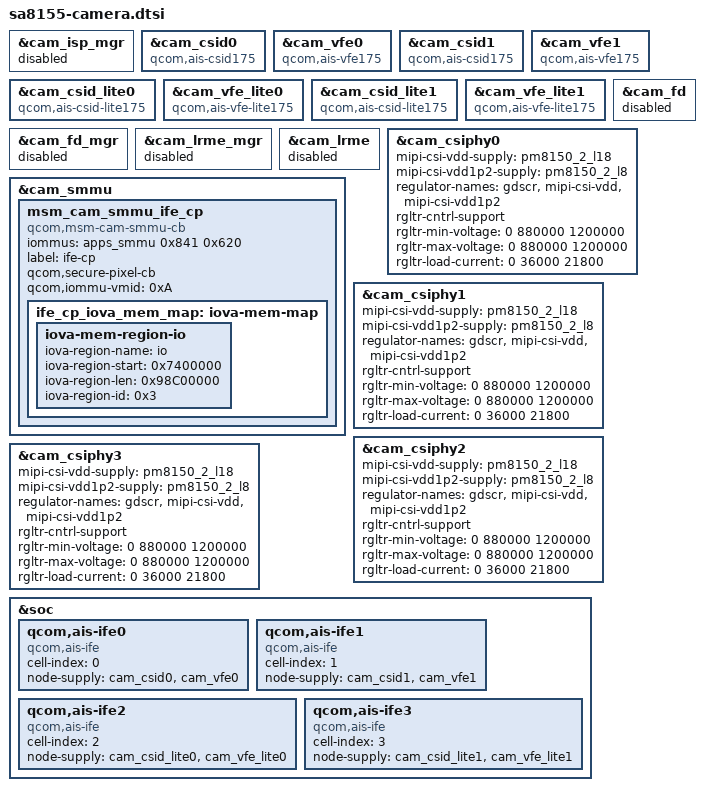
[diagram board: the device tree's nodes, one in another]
#include "sm8150-camera.dtsi"
#include "sa8155-camera-sensor.dtsi"

&cam_isp_mgr {
	status = "disabled";
};

&cam_csid0 {
	compatible = "qcom,ais-csid175";
};

&cam_vfe0 {
	compatible = "qcom,ais-vfe175";
};

&cam_csid1 {
	compatible = "qcom,ais-csid175";
};

&cam_vfe1 {
	compatible = "qcom,ais-vfe175";
};

&cam_csid_lite0 {
	compatible = "qcom,ais-csid-lite175";
};

&cam_vfe_lite0 {
	compatible = "qcom,ais-vfe-lite175";
};

&cam_csid_lite1 {
	compatible = "qcom,ais-csid-lite175";
};

&cam_vfe_lite1 {
	compatible = "qcom,ais-vfe-lite175";
};


&cam_fd_mgr {
	status = "disabled";
};
&cam_fd {
	status = "disabled";
};

&cam_lrme_mgr {
	status = "disabled";
};
&cam_lrme {
	status = "disabled";
};

&cam_smmu {
	msm_cam_smmu_ife_cp {
		compatible = "qcom,msm-cam-smmu-cb";
		iommus = <&apps_smmu 0x841 0x620>;
		label = "ife-cp";
		qcom,secure-pixel-cb;
		qcom,iommu-vmid = <0xA>; /* VMID_CP_PIXEL */
		ife_cp_iova_mem_map: iova-mem-map {
			/* IO region is approximately 2.5 GB */
			iova-mem-region-io {
				iova-region-name = "io";
				iova-region-start = <0x7400000>;
				iova-region-len = <0x98C00000>;
				iova-region-id = <0x3>;
				status = "ok";
			};
		};
	};
};

&cam_csiphy0 {
	mipi-csi-vdd-supply = <&pm8150_2_l18>;
	mipi-csi-vdd1p2-supply = <&pm8150_2_l8>;
	regulator-names = "gdscr", "mipi-csi-vdd", "mipi-csi-vdd1p2";
	rgltr-cntrl-support;
	rgltr-min-voltage = <0 880000 1200000>;
	rgltr-max-voltage = <0 880000 1200000>;
	rgltr-load-current = <0 36000 21800>;
};

&cam_csiphy1 {
	mipi-csi-vdd-supply = <&pm8150_2_l18>;
	mipi-csi-vdd1p2-supply = <&pm8150_2_l8>;
	regulator-names = "gdscr", "mipi-csi-vdd", "mipi-csi-vdd1p2";
	rgltr-cntrl-support;
	rgltr-min-voltage = <0 880000 1200000>;
	rgltr-max-voltage = <0 880000 1200000>;
	rgltr-load-current = <0 36000 21800>;
};

&cam_csiphy2 {
	mipi-csi-vdd-supply = <&pm8150_2_l18>;
	mipi-csi-vdd1p2-supply = <&pm8150_2_l8>;
	regulator-names = "gdscr", "mipi-csi-vdd", "mipi-csi-vdd1p2";
	rgltr-cntrl-support;
	rgltr-min-voltage = <0 880000 1200000>;
	rgltr-max-voltage = <0 880000 1200000>;
	rgltr-load-current = <0 36000 21800>;
};

&cam_csiphy3 {
	mipi-csi-vdd-supply = <&pm8150_2_l18>;
	mipi-csi-vdd1p2-supply = <&pm8150_2_l8>;
	regulator-names = "gdscr", "mipi-csi-vdd", "mipi-csi-vdd1p2";
	rgltr-cntrl-support;
	rgltr-min-voltage = <0 880000 1200000>;
	rgltr-max-voltage = <0 880000 1200000>;
	rgltr-load-current = <0 36000 21800>;
};

&soc {
	/delete-node/ cam_isp_mgr;
	/delete-node/ cam_fd_mgr;
	/delete-node/ cam_fd;
	/delete-node/ cam_lrme_mgr;
	/delete-node/ cam_lrme;

	qcom,ais-ife0 {
		compatible = "qcom,ais-ife";
		cell-index = <0>;
		status = "ok";
		node-supply=<&cam_csid0 &cam_vfe0>;
	};

	qcom,ais-ife1 {
		compatible = "qcom,ais-ife";
		cell-index = <1>;
		status = "ok";
		node-supply=<&cam_csid1 &cam_vfe1>;
	};

	qcom,ais-ife2 {
		compatible = "qcom,ais-ife";
		cell-index = <2>;
		status = "ok";
		node-supply=<&cam_csid_lite0 &cam_vfe_lite0>;
	};

	qcom,ais-ife3 {
		compatible = "qcom,ais-ife";
		cell-index = <3>;
		status = "ok";
		node-supply=<&cam_csid_lite1 &cam_vfe_lite1>;
	};
};
